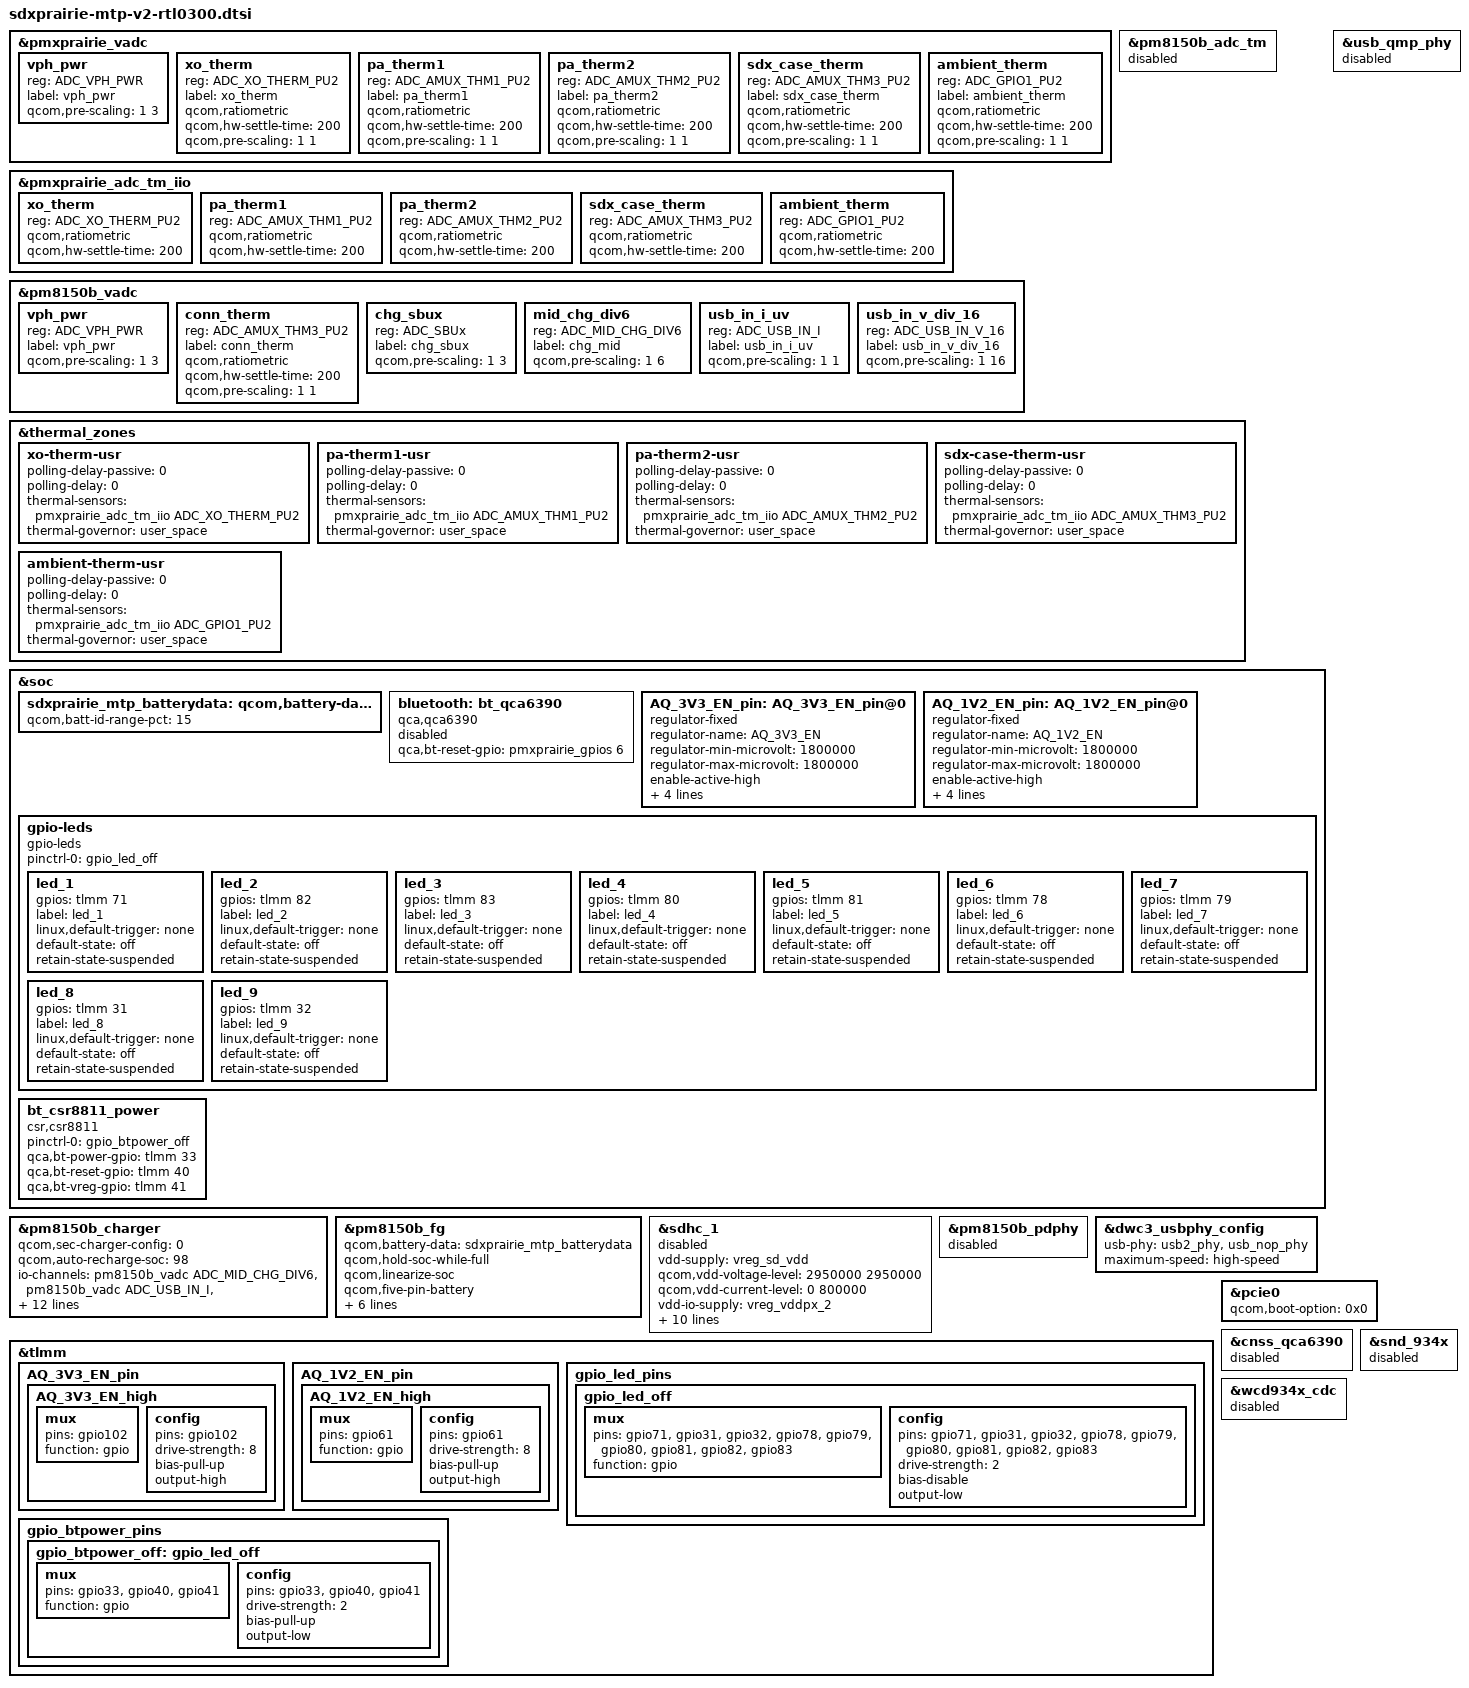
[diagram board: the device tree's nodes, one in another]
/* Copyright (c) 2018-2019, The Linux Foundation. All rights reserved.
 *
 * This program is free software; you can redistribute it and/or modify
 * it under the terms of the GNU General Public License version 2 and
 * only version 2 as published by the Free Software Foundation.
 *
 * This program is distributed in the hope that it will be useful,
 * but WITHOUT ANY WARRANTY; without even the implied warranty of
 * MERCHANTABILITY or FITNESS FOR A PARTICULAR PURPOSE.  See the
 * GNU General Public License for more details.
 */

#include "sdxprairie-pmic-overlay-rtl0300.dtsi"
#include "sdxprairie-mtp-audio-overlay.dtsi"

&pmxprairie_vadc {
	vph_pwr {
		reg = <ADC_VPH_PWR>;
		label = "vph_pwr";
		qcom,pre-scaling = <1 3>;
	};

	xo_therm {
		reg = <ADC_XO_THERM_PU2>;
		label = "xo_therm";
		qcom,ratiometric;
		qcom,hw-settle-time = <200>;
		qcom,pre-scaling = <1 1>;
	};

	pa_therm1 {
		reg = <ADC_AMUX_THM1_PU2>;
		label = "pa_therm1";
		qcom,ratiometric;
		qcom,hw-settle-time = <200>;
		qcom,pre-scaling = <1 1>;
	};

	pa_therm2 {
		reg = <ADC_AMUX_THM2_PU2>;
		label = "pa_therm2";
		qcom,ratiometric;
		qcom,hw-settle-time = <200>;
		qcom,pre-scaling = <1 1>;
	};

	sdx_case_therm {
		reg = <ADC_AMUX_THM3_PU2>;
		label = "sdx_case_therm";
		qcom,ratiometric;
		qcom,hw-settle-time = <200>;
		qcom,pre-scaling = <1 1>;
	};

	ambient_therm {
		reg = <ADC_GPIO1_PU2>;
		label = "ambient_therm";
		qcom,ratiometric;
		qcom,hw-settle-time = <200>;
		qcom,pre-scaling = <1 1>;
	};
};

&pmxprairie_adc_tm_iio {
	xo_therm {
		reg = <ADC_XO_THERM_PU2>;
		qcom,ratiometric;
		qcom,hw-settle-time = <200>;
	};

	pa_therm1 {
		reg = <ADC_AMUX_THM1_PU2>;
		qcom,ratiometric;
		qcom,hw-settle-time = <200>;
	};

	pa_therm2 {
		reg = <ADC_AMUX_THM2_PU2>;
		qcom,ratiometric;
		qcom,hw-settle-time = <200>;
	};

	sdx_case_therm {
		reg = <ADC_AMUX_THM3_PU2>;
		qcom,ratiometric;
		qcom,hw-settle-time = <200>;
	};

	ambient_therm {
		reg = <ADC_GPIO1_PU2>;
		qcom,ratiometric;
		qcom,hw-settle-time = <200>;
	};
};

&pm8150b_vadc {
	vph_pwr {
		reg = <ADC_VPH_PWR>;
		label = "vph_pwr";
		qcom,pre-scaling = <1 3>;
	};

	conn_therm {
		reg = <ADC_AMUX_THM3_PU2>;
		label = "conn_therm";
		qcom,ratiometric;
		qcom,hw-settle-time = <200>;
		qcom,pre-scaling = <1 1>;
	};

	chg_sbux {
		reg = <ADC_SBUx>;
		label = "chg_sbux";
		qcom,pre-scaling = <1 3>;
	};

	mid_chg_div6 {
		reg = <ADC_MID_CHG_DIV6>;
		label = "chg_mid";
		qcom,pre-scaling = <1 6>;
	};

	usb_in_i_uv {
		reg = <ADC_USB_IN_I>;
		label = "usb_in_i_uv";
		qcom,pre-scaling = <1 1>;
	};

	usb_in_v_div_16 {
		reg = <ADC_USB_IN_V_16>;
		label = "usb_in_v_div_16";
		qcom,pre-scaling = <1 16>;
	};
};

&pm8150b_adc_tm {
	status = "disabled";
};

&thermal_zones {
	xo-therm-usr {
		polling-delay-passive = <0>;
		polling-delay = <0>;
		thermal-sensors = <&pmxprairie_adc_tm_iio ADC_XO_THERM_PU2>;
		thermal-governor = "user_space";
	};

	pa-therm1-usr {
		polling-delay-passive = <0>;
		polling-delay = <0>;
		thermal-sensors = <&pmxprairie_adc_tm_iio ADC_AMUX_THM1_PU2>;
		thermal-governor = "user_space";
	};

	pa-therm2-usr {
		polling-delay-passive = <0>;
		polling-delay = <0>;
		thermal-sensors = <&pmxprairie_adc_tm_iio ADC_AMUX_THM2_PU2>;
		thermal-governor = "user_space";
	};

	sdx-case-therm-usr {
		polling-delay-passive = <0>;
		polling-delay = <0>;
		thermal-sensors = <&pmxprairie_adc_tm_iio ADC_AMUX_THM3_PU2>;
		thermal-governor = "user_space";
	};

	ambient-therm-usr {
		polling-delay-passive = <0>;
		polling-delay = <0>;
		thermal-sensors = <&pmxprairie_adc_tm_iio ADC_GPIO1_PU2>;
		thermal-governor = "user_space";
	};
};

&soc {
	sdxprairie_mtp_batterydata: qcom,battery-data {
		qcom,batt-id-range-pct = <15>;
		#include "fg-gen4-batterydata-alium-3600mah.dtsi"
	};
};

&soc {
	bluetooth: bt_qca6390 {
		compatible = "qca,qca6390";
		qca,bt-reset-gpio = <&pmxprairie_gpios 6 0>;
		/* askey@bruno 20190516, disable bt_qca6390 */
		status = "disabled"; 
	};
};

&pm8150b_charger {
	qcom,sec-charger-config = <0>;
	qcom,auto-recharge-soc = <98>;
	io-channels = <&pm8150b_vadc ADC_MID_CHG_DIV6>,
		      <&pm8150b_vadc ADC_USB_IN_I>,
		      <&pm8150b_vadc ADC_SBUx>,
		      <&pm8150b_vadc ADC_VPH_PWR>,
		      <&pm8150b_vadc ADC_CHG_TEMP>,
		      <&pm8150b_vadc ADC_USB_IN_V_16>;
	io-channel-names = "mid_voltage",
			   "usb_in_current",
			   "sbux_res",
			   "vph_voltage",
			   "chg_temp",
			   "usb_in_voltage";
	qcom,battery-data = <&sdxprairie_mtp_batterydata>;
	qcom,step-charging-enable;
	qcom,wd-bark-time-secs = <16>;
	qcom,suspend-input-on-debug-batt;
	qcom,hvdcp-autonomous-enable;
	qcom,hw-die-temp-mitigation;
	qcom,hw-connector-mitigation;
	qcom,hw-skin-temp-mitigation;
};

&pm8150b_fg {
	qcom,battery-data = <&sdxprairie_mtp_batterydata>;
	qcom,hold-soc-while-full;
	qcom,linearize-soc;
	qcom,five-pin-battery;
	/* ESR fast calibration */
	qcom,fg-esr-timer-chg-fast = <0 7>;
	qcom,fg-esr-timer-dischg-fast = <0 7>;
	qcom,fg-esr-timer-chg-slow = <0 96>;
	qcom,fg-esr-timer-dischg-slow = <0 96>;
	qcom,fg-esr-cal-soc-thresh = <26 230>;
	qcom,fg-esr-cal-temp-thresh = <10 40>;
};

&sdhc_1 {
	vdd-supply = <&vreg_sd_vdd>;
	qcom,vdd-voltage-level = <2950000 2950000>;
	qcom,vdd-current-level = <0 800000>;

	vdd-io-supply = <&vreg_vddpx_2>;
	qcom,vdd-io-voltage-level = <1800000 2850000>;
	qcom,vdd-io-current-level = <0 10000>;

	pinctrl-names = "active", "sleep";
	pinctrl-0 = <&sdc1_clk_on &sdc1_cmd_on &sdc1_data_on &sdc1_cd_on>;
	pinctrl-1 = <&sdc1_clk_off &sdc1_cmd_off &sdc1_data_off &sdc1_cd_off>;

	qcom,clk-rates = <400000 20000000 25000000 50000000 100000000
								200000000>;
	qcom,devfreq,freq-table = <50000000 200000000>;

	cd-gpios = <&tlmm 99 GPIO_ACTIVE_LOW>;
	/* askey@bruno 20190516, disable sdhc */
	status = "disabled";  
};

/* askey@bruno 20190516, Remove pm8150b charger, Kernel changes to support USB peripheral mode */
&pm8150b_pdphy {
  status = "disabled";
};

/* askey@bruno 20190516, Remove pm8150b charger, Kernel changes to support USB peripheral mode */
&dwc3_usbphy_config
{
  usb-phy = <&usb2_phy>, <&usb_nop_phy>;     
  maximum-speed = "high-speed"; 
};

/* askey@bruno 20190516, Remove pm8150b charger, Kernel changes to support USB peripheral mode */
&usb_qmp_phy
{
  status = "disabled";
};

/* askey@bruno 20190516, add aqc111 3V3 and 1V2 enable pin for power control */
&tlmm {
  AQ_3V3_EN_pin {
    AQ_3V3_EN_high: AQ_3V3_EN_high {
      mux {
        pins = "gpio102";
        function = "gpio";
      };
      
      config {
        pins = "gpio102";
        drive-strength = <8>;
        bias-pull-up;
        output-high;
      };
    };
  };
  
  AQ_1V2_EN_pin {
    AQ_1V2_EN_high: AQ_1V2_EN_high {
      mux {
        pins = "gpio61";
        function = "gpio";
      };
      
      config {
        pins = "gpio61";
        drive-strength = <8>;
        bias-pull-up;
        output-high;
      };
    };
  };  
  
  /*askey@bruno 20190517, add gpio-leds defines*/
  gpio_led_pins {
    gpio_led_off: gpio_led_off {
      mux {
        pins = "gpio71","gpio31","gpio32","gpio78","gpio79","gpio80","gpio81","gpio82","gpio83";
        function = "gpio";
      };

      config {
        pins = "gpio71","gpio31","gpio32","gpio78","gpio79","gpio80","gpio81","gpio82","gpio83";
        drive-strength = <2>;
        bias-disable;
        output-low;
      };
    };
  };

  /*askey@bruno 20190517, add btpower gpio default bias set pull up*/
  gpio_btpower_pins {
    gpio_btpower_off: gpio_led_off {
      mux {
        pins = "gpio33","gpio40","gpio41";
        function = "gpio";
      };

      config {
        pins = "gpio33","gpio40","gpio41";
        drive-strength = <2>;
        bias-pull-up;
        output-low;
      };
    };
  };
  
};

/* askey@bruno 20190516, add aqc111 3V3 and 1V2 enable pin for power control */
&soc {
  AQ_3V3_EN_pin: AQ_3V3_EN_pin@0 {
    compatible = "regulator-fixed";
    regulator-name = "AQ_3V3_EN";
    regulator-min-microvolt = <1800000>;
    regulator-max-microvolt = <1800000>;
    enable-active-high;
    gpio = <&tlmm 102 0>;
    regulator-boot-on;
    regulator-always-on;
    pinctrl-names = "AQ_3V3_EN";
    pintctrl-0 = <&AQ_3V3_EN_high>;
    status = "okay";
  };
  
  AQ_1V2_EN_pin: AQ_1V2_EN_pin@0 {
    compatible = "regulator-fixed";
    regulator-name = "AQ_1V2_EN";
    regulator-min-microvolt = <1800000>;
    regulator-max-microvolt = <1800000>;
    enable-active-high;
    gpio = <&tlmm 61 0>;
    regulator-boot-on;
    regulator-always-on;
    pinctrl-names = "AQ_1V2_EN";
    pintctrl-0 = <&AQ_1V2_EN_high>;
    status = "okay";
  };
    
};

&pcie0 {
  qcom,boot-option = <0x0>;  // askey@bruno 20190516, Enable PCIE probe enumeration, change from 1 to 0.
};

/* askey@bruno 20190516, disable WiFi */
&cnss_qca6390
{
  status = "disabled";  
};
/* askey@bruno 20190516, disable Audio snd */
&snd_934x
{
  status = "disabled"; 
};
/* askey@bruno 20190516, disable Audio Codec */
&wcd934x_cdc
{
  status = "disabled"; 
};

&soc {
  /*askey@bruno 20190517, add gpio-leds driver gpio configs*/
  /*askey@mike 20200110, modify gpio-leds definition for RTL0300 DV4*/  
  gpio-leds {
    compatible = "gpio-leds";
    status = "okay";
    pinctrl-names = "default";
    pinctrl-0 = <&gpio_led_off>;
    
    led_1{
      gpios = <&tlmm 71 0>;
      label = "led_1";
      linux,default-trigger = "none";
      default-state = "off";
      retain-state-suspended;
    };
    led_2{
      gpios = <&tlmm 82 0>;
      label = "led_2";
      linux,default-trigger = "none";
      default-state = "off";
      retain-state-suspended;
    };
    led_3{
      gpios = <&tlmm 83 0>;
      label = "led_3";
      linux,default-trigger = "none";
      default-state = "off";
      retain-state-suspended;
    };
    led_4{
      gpios = <&tlmm 80 0>;
      label = "led_4";
      linux,default-trigger = "none";
      default-state = "off";
      retain-state-suspended;
    };
    led_5{
      gpios = <&tlmm 81 0>;
      label = "led_5";
      linux,default-trigger = "none";
      default-state = "off";
      retain-state-suspended;
    };
    led_6{
      gpios = <&tlmm 78 0>;
      label = "led_6";
      linux,default-trigger = "none";
      default-state = "off";
      retain-state-suspended;
    };
    led_7{
      gpios = <&tlmm 79 0>;
      label = "led_7";
      linux,default-trigger = "none";
      default-state = "off";
      retain-state-suspended;
    };
    led_8{
      gpios = <&tlmm 31 0>;
      label = "led_8";
      linux,default-trigger = "none";
      default-state = "off";
      retain-state-suspended;
    };
    led_9{
      gpios = <&tlmm 32 0>;
      label = "led_9";
      linux,default-trigger = "none";
      default-state = "off";
      retain-state-suspended;
    };                                     
  };
  
  /* askey@bruno 20180131, add bt_csr8811 configs */
  bt_csr8811_power: bt_csr8811_power {
    compatible = "csr,csr8811";
    
    pinctrl-names = "default";
    pinctrl-0 = <&gpio_btpower_off>;
        
    qca,bt-power-gpio = <&tlmm 33 0>; /* BT_POWER_EN */
    qca,bt-reset-gpio = <&tlmm 40 0>; /* BT_EN/BT_RESET */
    qca,bt-vreg-gpio = <&tlmm 41 0>; /* BT_VREG_EN */
  };

  
}; 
